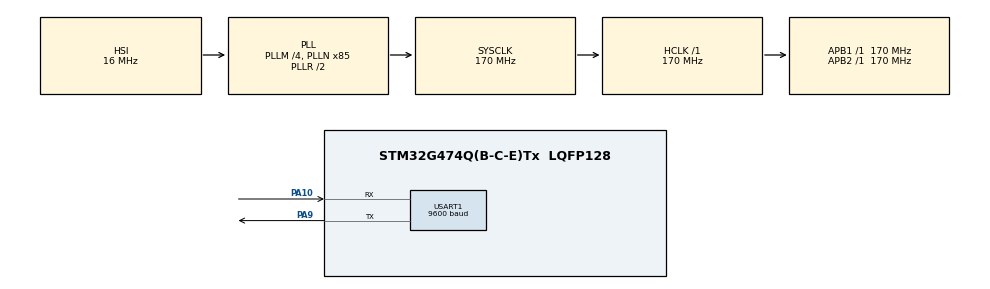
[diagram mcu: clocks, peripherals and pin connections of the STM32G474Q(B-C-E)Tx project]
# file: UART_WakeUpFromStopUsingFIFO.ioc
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Mcu.Family=STM32G4
Mcu.Name=STM32G474Q(B-C-E)Tx
Mcu.Package=LQFP128
NVIC.PriorityGroup=NVIC_PRIORITYGROUP_4
NVIC.USART1_IRQn=true\:1\:0\:true\:false\:true\:true\:true\:true
PA10.GPIO_PuPd=GPIO_PULLUP
PA10.GPIO_Speed=GPIO_SPEED_FREQ_HIGH
PA10.Mode=Asynchronous
PA10.Signal=USART1_RX
PA9.GPIO_PuPd=GPIO_PULLUP
PA9.GPIO_Speed=GPIO_SPEED_FREQ_HIGH
PA9.Mode=Asynchronous
PA9.Signal=USART1_TX
ProjectManager.HeapSize=0x200
ProjectManager.StackSize=0x400
ProjectManager.TargetToolchain=EWARM V8.32
RCC.ADC12Freq_Value=170000000
RCC.ADC345Freq_Value=170000000
RCC.AHBFreq_Value=170000000
RCC.APB1Freq_Value=170000000
RCC.APB1TimFreq_Value=170000000
RCC.APB2Freq_Value=170000000
RCC.APB2TimFreq_Value=170000000
RCC.CortexFreq_Value=170000000
RCC.EXTERNAL_CLOCK_VALUE=12288000
RCC.HCLKFreq_Value=170000000
RCC.HSE_VALUE=24000000
RCC.HSI48_VALUE=48000000
RCC.HSI_VALUE=16000000
RCC.LPUART1CLockSelection=RCC_LPUART1CLKSOURCE_HSI
RCC.LSE_VALUE=32768
RCC.PLLM=RCC_PLLM_DIV4
RCC.PLLN=85
RCC.SYSCLKFreq_VALUE=170000000
RCC.SYSCLKSource=RCC_SYSCLKSOURCE_PLLCLK
RCC.UART4CLockSelection=RCC_UART4CLKSOURCE_HSI
RCC.UART5CLockSelection=RCC_UART5CLKSOURCE_HSI
RCC.USART1CLockSelection=RCC_USART1CLKSOURCE_HSI
RCC.USART2CLockSelection=RCC_USART2CLKSOURCE_HSI
RCC.USART3CLockSelection=RCC_USART3CLKSOURCE_HSI
RCC.USBFreq_Value=170000000
RCC.VCOOutputFreq_Value=340000000
USART1.BaudRate=9600
USART1.DMADisableonRxErrorParam-Asynchronous=ADVFEATURE_DMA_ENABLEONRXERROR
USART1.DataInvertParam-Asynchronous=ADVFEATURE_DATAINV_DISABLE
USART1.FIFOMode=FIFOMODE_ENABLE
USART1.MSBFirstParam-Asynchronous=ADVFEATURE_MSBFIRST_DISABLE
USART1.Mode-Asynchronous=MODE_TX_RX
USART1.OneBitSampling=UART_ONE_BIT_SAMPLE_DISABLE
USART1.OverrunDisableParam-Asynchronous=ADVFEATURE_OVERRUN_ENABLE
USART1.Parity-Asynchronous=PARITY_ODD
USART1.Prescaler=UART_PRESCALER_DIV1
USART1.RXFIFOThreshold=RXFIFO_THRESHOLD_1QUARTERFULL
USART1.RXFIFOThreshold-Asynchronous=RXFIFO_THRESHOLD_1QUARTERFULL
USART1.RxPinLevelInvertParam-Asynchronous=ADVFEATURE_RXINV_DISABLE
USART1.StopBits-Asynchronous=STOPBITS_1
USART1.SwapParam-Asynchronous=ADVFEATURE_SWAP_DISABLE
USART1.TXFIFOThreshold=TXFIFO_THRESHOLD_1QUARTERFULL
USART1.TXFIFOThreshold-Asynchronous=TXFIFO_THRESHOLD_1QUARTERFULL
USART1.TxPinLevelInvertParam-Asynchronous=ADVFEATURE_TXINV_DISABLE
USART1.VirtualMode-Asynchronous=VM_ASYNC
USART1.WordLength=WORDLENGTH_8B
VP_SYS_VS_DBSignals.Mode=DisableDeadBatterySignals
board=custom

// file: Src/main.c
/* USER CODE BEGIN Header */
/**
  ******************************************************************************
  * @file    UART/UART_WakeUpFromStopUsingFIFO/Src/main.c
  * @author  MCD Application Team
  * @brief   This sample code shows how to use UART HAL API (UART instance)
  *          to wake up the MCU from STOP mode using the UART FIFO level.
  *          Two boards are used, one which enters STOP mode and the second
  *          one which sends the wake-up stimuli.
  ******************************************************************************
  * @attention
  *
  * Copyright (c) 2019 STMicroelectronics.
  * All rights reserved.
  *
  * This software is licensed under terms that can be found in the LICENSE file
  * in the root directory of this software component.
  * If no LICENSE file comes with this software, it is provided AS-IS.
  *
  ******************************************************************************
  */
/* USER CODE END Header */
#include "main.h"

/* USER CODE BEGIN Includes */
#include "stm32g474e_eval.h"
/* USER CODE END Includes */

/* USER CODE BEGIN PM */
#define HAL_TIMEOUT_VALUE 0xFFFFFFFF
#define countof(a) (sizeof(a) / sizeof(*(a)))
/* USER CODE END PM */

UART_HandleTypeDef huart1;

/* USER CODE BEGIN PV */
uint8_t HeaderTxBuffer[] = "\r\nUART WakeUp from stop mode using FIFO\r\n";
uint8_t Part1TxBuffer[] = "\r\n\t Part 1: RXFIFO threshold interrupt\r\n   Waiting for characters reception until RX FIFO threshold is reached\r\n   Please send 2 bytes\r\n";
uint8_t WakeupRXFTBuffer[] = "\r\n   Proper wakeup based on RXFIFO threshold interrupt detection.\r\n";
uint8_t Part2TxBuffer[] = "\r\n\t Part 2: RXFIFO full interrupt\r\n   Waiting for characters reception until RX FIFO is Full \r\n   Please send 8 bytes\r\n";
uint8_t WakeupRXFFBuffer[] = "\r\n   Proper wakeup based on RXFIFO full interrupt detection.\r\n";
uint8_t FooterTxBuffer[] = "\r\nExample finished successfully\r\n";

uint8_t RxBuffer[8];
/* USER CODE END PV */

void SystemClock_Config(void);
static void MX_GPIO_Init(void);
static void MX_USART1_UART_Init(void);

int main(void)
{

  /* MCU Configuration--------------------------------------------------------*/

  /* Reset of all peripherals, Initializes the Flash interface and the Systick. */
  HAL_Init();

  /* Configure the system clock */
  SystemClock_Config();

  /* USER CODE BEGIN SysInit */
  /* Initialize BSP LEDs */
  BSP_LED_Init(LED1);
  BSP_LED_Init(LED3);
  /* USER CODE END SysInit */

  /* Initialize all configured peripherals */
  MX_GPIO_Init();
  MX_USART1_UART_Init();
  /* USER CODE BEGIN 2 */

  /* Turn LED1 on */
  BSP_LED_On(LED1);

  /*##########################################################################*/
  /*##-1- Wakeup first step RXFT #############################################*/
  /*##########################################################################*/

  /* Output message on hyperterminal */
  HAL_UART_Transmit(&huart1, (uint8_t*)&HeaderTxBuffer, countof(HeaderTxBuffer)-1, HAL_TIMEOUT_VALUE);

  /* Enable MCU wakeup by UART */
  HAL_UARTEx_EnableStopMode(&huart1);

  /* Enable the UART RX FIFO threshold interrupt */
  __HAL_UART_ENABLE_IT(&huart1, UART_IT_RXFT);

  /* Enable the UART wakeup from stop mode interrupt */
  __HAL_UART_ENABLE_IT(&huart1, UART_IT_WUF);

  /* Output message on hyperterminal */
  HAL_UART_Transmit(&huart1, (uint8_t*)&Part1TxBuffer, countof(Part1TxBuffer)-1, HAL_TIMEOUT_VALUE);

  /* Put UART peripheral in reception process */
  HAL_UART_Receive_IT(&huart1, (uint8_t*)&RxBuffer, 2);

  /* Turn LED1 off */
  BSP_LED_Off(LED1);

  /* Enter STOP mode */
  HAL_PWR_EnterSTOPMode(PWR_MAINREGULATOR_ON,PWR_STOPENTRY_WFI);

  /* ... STOP Mode ... */

  /* Turn LED1 on */
  BSP_LED_On(LED1);

  while(HAL_UART_GetState(&huart1) != HAL_UART_STATE_READY)
  {
  }

  /* Disable the UART wakeup from stop mode interrupt */
  __HAL_UART_DISABLE_IT(&huart1, UART_IT_WUF);

  /* Disable the UART RX FIFO threshold interrupt */
  __HAL_UART_DISABLE_IT(&huart1, UART_IT_RXFT);

  /* Disable UART Stop Mode */
  HAL_UARTEx_DisableStopMode(&huart1);

  /* Output message on hyperterminal */
  HAL_UART_Transmit(&huart1, (uint8_t*)&WakeupRXFTBuffer, countof(WakeupRXFTBuffer)-1, HAL_TIMEOUT_VALUE);

  /*##########################################################################*/
  /*##-2- Wakeup second step RXFF ############################################*/
  /*##########################################################################*/

  /* Update Rx FIFO threshold */
  if (HAL_UARTEx_SetRxFifoThreshold(&huart1, UART_RXFIFO_THRESHOLD_8_8) != HAL_OK)
  {
    Error_Handler();
  }

  /* Enable MCU wakeup by UART */
  HAL_UARTEx_EnableStopMode(&huart1);

  /* Enable the UART RX FIFO full interrupt */
  __HAL_UART_ENABLE_IT(&huart1, UART_IT_RXFF);

  /* Enable the UART wakeup from stop mode interrupt */
  __HAL_UART_ENABLE_IT(&huart1, UART_IT_WUF);

  /* Output message on hyperterminal */
  HAL_UART_Transmit(&huart1, (uint8_t*)&Part2TxBuffer, countof(Part2TxBuffer)-1, HAL_TIMEOUT_VALUE);

  /* Put UART peripheral in reception process */
  HAL_UART_Receive_IT(&huart1, (uint8_t*)&RxBuffer, 8);

  /* Turn LED1 off */
  BSP_LED_Off(LED1);

  /* Enter STOP mode */
  HAL_PWR_EnterSTOPMode(PWR_MAINREGULATOR_ON,PWR_STOPENTRY_WFI);

  /* ... STOP Mode ... */

  /* Turn LED1 on */
  BSP_LED_On(LED1);

  while(HAL_UART_GetState(&huart1) != HAL_UART_STATE_READY)
  {
  }

  /* Disable the UART wakeup from stop mode interrupt */
  __HAL_UART_DISABLE_IT(&huart1, UART_IT_WUF);

  /* Disable the UART RX FIFO full interrupt */
  __HAL_UART_DISABLE_IT(&huart1, UART_IT_RXFF);

  /* Disable UART Stop Mode */
  HAL_UARTEx_DisableStopMode(&huart1);

  /* Output message on hyperterminal */
  HAL_UART_Transmit(&huart1, (uint8_t*)&WakeupRXFFBuffer, countof(WakeupRXFFBuffer)-1, HAL_TIMEOUT_VALUE);

  /*##########################################################################*/
  /*##-3- Successful test ####################################################*/
  /*##########################################################################*/

  /* Output message on hyperterminal */
  HAL_UART_Transmit(&huart1, (uint8_t*)&FooterTxBuffer, countof(FooterTxBuffer)-1, HAL_TIMEOUT_VALUE);
  /* USER CODE END 2 */

  /* Infinite loop */
  while (1)
  {

  }
}

void SystemClock_Config(void)
{
  RCC_OscInitTypeDef RCC_OscInitStruct = {0};
  RCC_ClkInitTypeDef RCC_ClkInitStruct = {0};

  /** Configure the main internal regulator output voltage
  */
  HAL_PWREx_ControlVoltageScaling(PWR_REGULATOR_VOLTAGE_SCALE1_BOOST);

  /** Initializes the RCC Oscillators according to the specified parameters
  * in the RCC_OscInitTypeDef structure.
  */
  RCC_OscInitStruct.OscillatorType = RCC_OSCILLATORTYPE_HSI;
  RCC_OscInitStruct.HSIState = RCC_HSI_ON;
  RCC_OscInitStruct.HSICalibrationValue = RCC_HSICALIBRATION_DEFAULT;
  RCC_OscInitStruct.PLL.PLLState = RCC_PLL_ON;
  RCC_OscInitStruct.PLL.PLLSource = RCC_PLLSOURCE_HSI;
  RCC_OscInitStruct.PLL.PLLM = RCC_PLLM_DIV4;
  RCC_OscInitStruct.PLL.PLLN = 85;
  RCC_OscInitStruct.PLL.PLLP = RCC_PLLP_DIV2;
  RCC_OscInitStruct.PLL.PLLQ = RCC_PLLQ_DIV2;
  RCC_OscInitStruct.PLL.PLLR = RCC_PLLR_DIV2;
  if (HAL_RCC_OscConfig(&RCC_OscInitStruct) != HAL_OK)
  {
    Error_Handler();
  }

  /** Initializes the CPU, AHB and APB buses clocks
  */
  RCC_ClkInitStruct.ClockType = RCC_CLOCKTYPE_HCLK|RCC_CLOCKTYPE_SYSCLK
                              |RCC_CLOCKTYPE_PCLK1|RCC_CLOCKTYPE_PCLK2;
  RCC_ClkInitStruct.SYSCLKSource = RCC_SYSCLKSOURCE_PLLCLK;
  RCC_ClkInitStruct.AHBCLKDivider = RCC_SYSCLK_DIV1;
  RCC_ClkInitStruct.APB1CLKDivider = RCC_HCLK_DIV1;
  RCC_ClkInitStruct.APB2CLKDivider = RCC_HCLK_DIV1;

  if (HAL_RCC_ClockConfig(&RCC_ClkInitStruct, FLASH_LATENCY_4) != HAL_OK)
  {
    Error_Handler();
  }
}

static void MX_USART1_UART_Init(void)
{

  huart1.Instance = USART1;
  huart1.Init.BaudRate = 9600;
  huart1.Init.WordLength = UART_WORDLENGTH_8B;
  huart1.Init.StopBits = UART_STOPBITS_1;
  huart1.Init.Parity = UART_PARITY_ODD;
  huart1.Init.Mode = UART_MODE_TX_RX;
  huart1.Init.HwFlowCtl = UART_HWCONTROL_NONE;
  huart1.Init.OverSampling = UART_OVERSAMPLING_16;
  huart1.Init.OneBitSampling = UART_ONE_BIT_SAMPLE_DISABLE;
  huart1.Init.ClockPrescaler = UART_PRESCALER_DIV1;
  huart1.AdvancedInit.AdvFeatureInit = UART_ADVFEATURE_NO_INIT;
  if (HAL_UART_Init(&huart1) != HAL_OK)
  {
    Error_Handler();
  }
  if (HAL_UARTEx_SetTxFifoThreshold(&huart1, UART_TXFIFO_THRESHOLD_1_4) != HAL_OK)
  {
    Error_Handler();
  }
  if (HAL_UARTEx_SetRxFifoThreshold(&huart1, UART_RXFIFO_THRESHOLD_1_4) != HAL_OK)
  {
    Error_Handler();
  }
  if (HAL_UARTEx_EnableFifoMode(&huart1) != HAL_OK)
  {
    Error_Handler();
  }

}

static void MX_GPIO_Init(void)
{

  /* GPIO Ports Clock Enable */
  __HAL_RCC_GPIOA_CLK_ENABLE();

}

void Error_Handler(void)
{
  /* USER CODE BEGIN Error_Handler_Debug */
  /* User can add his own implementation to report the HAL error return state */
  while(1)
  {
    /* LED3 is blinking */
    BSP_LED_Toggle(LED3);
    HAL_Delay(500);
  }
  /* USER CODE END Error_Handler_Debug */
}
